VERSION ""

NS_ :

BS_:

BU_: RF_CT3

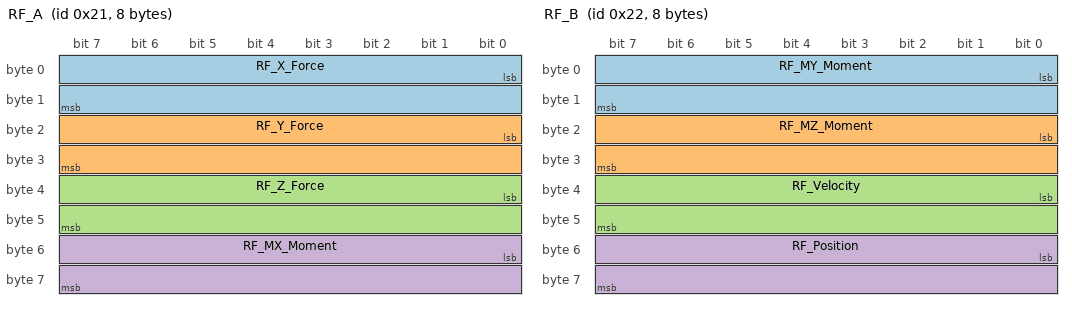
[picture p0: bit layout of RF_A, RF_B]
BO_ 33 RF_A: 8 RF_CT3
 SG_ RF_X_Force : 0|16@1- (0.274424979248047,0) [-8992|8992] "lbf" Vector__XXX
 SG_ RF_Y_Force : 16|16@1- (0.137212489624023,0) [-4496|4496] "lbf" Vector__XXX
 SG_ RF_Z_Force : 32|16@1- (0.274424979248047,0) [-8992|8992] "lbf" Vector__XXX
 SG_ RF_MX_Moment : 48|16@1- (0.135051663024902,0) [-4425|4425] "lb-ft" Vector__XXX

BO_ 34 RF_B: 8 RF_CT3
 SG_ RF_MY_Moment : 0|16@1- (0.135051663024902,0) [-4425|4425] "lb-ft" Vector__XXX
 SG_ RF_MZ_Moment : 16|16@1- (0.135051663024902,0) [-4425|4425] "lb-ft" Vector__XXX
 SG_ RF_Velocity : 32|16@1- (0.06103515625,0) [-2000|2000] "rpm" Vector__XXX
 SG_ RF_Position : 48|16@1- (0.010986328125,0) [0|360] "degrees" Vector__XXX

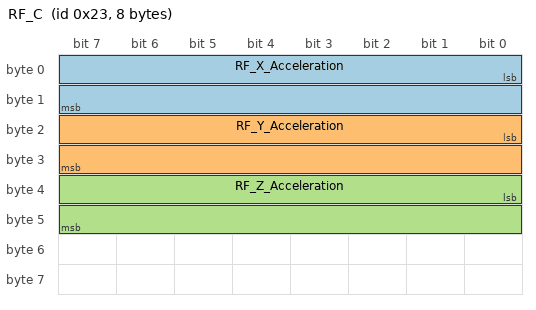
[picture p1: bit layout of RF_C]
BO_ 35 RF_C: 8 RF_CT3
 SG_ RF_X_Acceleration : 0|16@1- (0.0030517578125,0) [-100|100] "g" Vector__XXX
 SG_ RF_Y_Acceleration : 16|16@1- (0.0030517578125,0) [-100|100] "g" Vector__XXX
 SG_ RF_Z_Acceleration : 32|16@1- (0.0030517578125,0) [-100|100] "g" Vector__XXX
